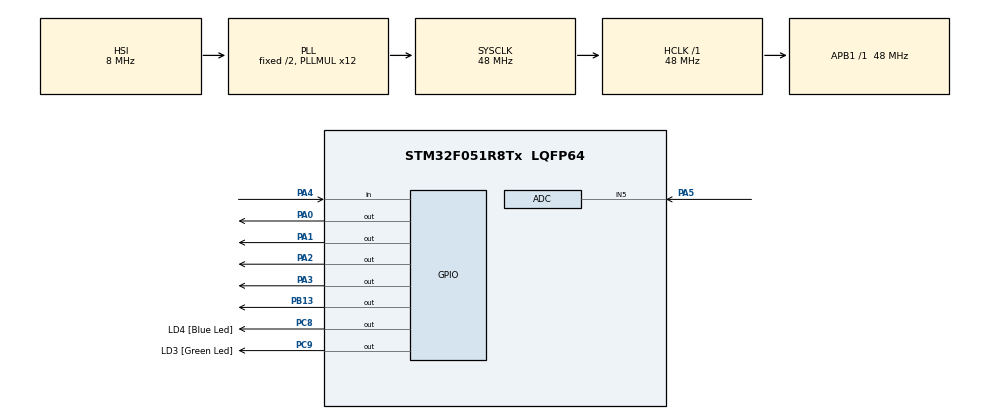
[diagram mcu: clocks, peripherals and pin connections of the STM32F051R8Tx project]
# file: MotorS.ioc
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ADC.ContinuousConvMode=ENABLE
Mcu.Family=STM32F0
Mcu.Name=STM32F051R8Tx
Mcu.Package=LQFP64
PA0.Signal=GPIO_Output
PA1.Signal=GPIO_Output
PA13.GPIO_Label=SWDIO
PA13.Mode=Serial_Wire
PA13.Signal=SYS_SWDIO
PA14.GPIO_Label=SWCLK
PA14.Mode=Serial_Wire
PA14.Signal=SYS_SWCLK
PA2.Signal=GPIO_Output
PA3.Signal=GPIO_Output
PA4.GPIO_PuPd=GPIO_PULLUP
PA4.Signal=GPIO_Input
PA5.Mode=IN5
PA5.Signal=ADC_IN5
PB13.Signal=GPIO_Output
PC8.GPIO_Label=LD4 [Blue Led]
PC8.Signal=GPIO_Output
PC9.GPIO_Label=LD3 [Green Led]
PC9.Signal=GPIO_Output
PF0-OSC_IN.Mode=HSE-External-Oscillator
PF0-OSC_IN.Signal=RCC_OSC_IN
PF1-OSC_OUT.Mode=HSE-External-Oscillator
PF1-OSC_OUT.Signal=RCC_OSC_OUT
ProjectManager.HeapSize=0x200
ProjectManager.StackSize=0x400
ProjectManager.TargetToolchain=STM32CubeIDE
RCC.AHBFreq_Value=48000000
RCC.APB1Freq_Value=48000000
RCC.APB1TimFreq_Value=48000000
RCC.HCLKFreq_Value=48000000
RCC.PLLMUL=RCC_PLL_MUL12
RCC.SYSCLKFreq_VALUE=48000000
RCC.SYSCLKSource=RCC_SYSCLKSOURCE_PLLCLK
TIM2.Prescaler=71
VP_TIM2_VS_ClockSourceINT.Mode=Internal
board=STM32F0DISCOVERY

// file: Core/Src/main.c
/* USER CODE BEGIN Header */
/**
  ******************************************************************************
  * @file           : main.c
  * @brief          : Main program body
  ******************************************************************************
  * @attention
  *
  * Copyright (c) 2024 STMicroelectronics.
  * All rights reserved.
  *
  * This software is licensed under terms that can be found in the LICENSE file
  * in the root directory of this software component.
  * If no LICENSE file comes with this software, it is provided AS-IS.
  *
  ******************************************************************************
  */
/* USER CODE END Header */
#include "main.h"

ADC_HandleTypeDef hadc;

TIM_HandleTypeDef htim2;

void SystemClock_Config(void);
static void MX_GPIO_Init(void);
static void MX_TIM2_Init(void);
static void MX_ADC_Init(void);

/* USER CODE BEGIN 0 */
int readValue;
#define IN1_PIN GPIO_PIN_0
#define IN1_PORT GPIOA
#define IN2_PIN GPIO_PIN_1
#define IN2_PORT GPIOA
#define IN3_PIN GPIO_PIN_2
#define IN3_PORT GPIOA
#define IN4_PIN GPIO_PIN_3
#define IN4_PORT GPIOA
int stepNumber;          // which step the motor is on

void motorDelay(uint32_t delay)
{
    if (delay < 6000)
    {
        __HAL_TIM_SET_COUNTER(&htim2, 0);
        while (__HAL_TIM_GET_COUNTER(&htim2) < delay);
    }
    else
    {
        HAL_Delay(delay/1000);
    }
}

void motorOn()
{
    // Find out which step the motor is on
    switch (stepNumber)
    {
      case 1:
          HAL_GPIO_WritePin(IN1_PORT, IN1_PIN, GPIO_PIN_SET);   // IN1
          HAL_GPIO_WritePin(IN2_PORT, IN2_PIN, GPIO_PIN_RESET); // IN2
          HAL_GPIO_WritePin(IN3_PORT, IN3_PIN, GPIO_PIN_RESET); // IN3
          HAL_GPIO_WritePin(IN4_PORT, IN4_PIN, GPIO_PIN_SET);   // IN4
          HAL_Delay(5);
        break;
      case 2:
          HAL_GPIO_WritePin(IN1_PORT, IN1_PIN, GPIO_PIN_SET);   // IN1
          HAL_GPIO_WritePin(IN2_PORT, IN2_PIN, GPIO_PIN_RESET); // IN2
          HAL_GPIO_WritePin(IN3_PORT, IN3_PIN, GPIO_PIN_SET);   // IN3
          HAL_GPIO_WritePin(IN4_PORT, IN4_PIN, GPIO_PIN_RESET); // IN4
          HAL_Delay(5);
        break;
      case 3:
          HAL_GPIO_WritePin(IN1_PORT, IN1_PIN, GPIO_PIN_RESET); // IN1
          HAL_GPIO_WritePin(IN2_PORT, IN2_PIN, GPIO_PIN_SET);   // IN2
          HAL_GPIO_WritePin(IN3_PORT, IN3_PIN, GPIO_PIN_SET);   // IN3
          HAL_GPIO_WritePin(IN4_PORT, IN4_PIN, GPIO_PIN_RESET); // IN4
          HAL_Delay(5);
        break;
      case 4:
          HAL_GPIO_WritePin(IN1_PORT, IN1_PIN, GPIO_PIN_RESET); // IN1
          HAL_GPIO_WritePin(IN2_PORT, IN2_PIN, GPIO_PIN_SET);   // IN2
          HAL_GPIO_WritePin(IN3_PORT, IN3_PIN, GPIO_PIN_RESET); // IN3
          HAL_GPIO_WritePin(IN4_PORT, IN4_PIN, GPIO_PIN_SET);   // IN4
          HAL_Delay(5);
        break;
      default:
        break;
    }
}
void motorOff()
{
    // Switch off the idle current to the motor
    // Otherwise L298N module will heat up
    HAL_GPIO_WritePin(IN1_PORT, IN1_PIN, GPIO_PIN_RESET); // IN1
    HAL_GPIO_WritePin(IN2_PORT, IN2_PIN, GPIO_PIN_RESET); // IN2
    HAL_GPIO_WritePin(IN3_PORT, IN3_PIN, GPIO_PIN_RESET); // IN3
    HAL_GPIO_WritePin(IN4_PORT, IN4_PIN, GPIO_PIN_RESET); // IN4
}
void stepCV (int steps, float speed) // CV - Clockwise
{
  uint32_t delay = 60*1000*1000/200/speed;
  for(int x=0; x<steps; x=x+1)
  {
    // Step to the next step
    switch (stepNumber)
    {
      case 1:
        HAL_GPIO_WritePin(IN1_PORT, IN1_PIN, GPIO_PIN_SET);   // IN1
        HAL_GPIO_WritePin(IN2_PORT, IN2_PIN, GPIO_PIN_RESET); // IN2
        HAL_GPIO_WritePin(IN3_PORT, IN3_PIN, GPIO_PIN_SET);   // IN3
        HAL_GPIO_WritePin(IN4_PORT, IN4_PIN, GPIO_PIN_RESET); // IN4
        motorDelay(delay);
        stepNumber = 2;
        break;
      case 2:
        HAL_GPIO_WritePin(IN1_PORT, IN1_PIN, GPIO_PIN_RESET); // IN1
        HAL_GPIO_WritePin(IN2_PORT, IN2_PIN, GPIO_PIN_SET);   // IN2
        HAL_GPIO_WritePin(IN3_PORT, IN3_PIN, GPIO_PIN_SET);   // IN3
        HAL_GPIO_WritePin(IN4_PORT, IN4_PIN, GPIO_PIN_RESET); // IN4
        motorDelay(delay);
        stepNumber = 3;
        break;
      case 3:

        HAL_GPIO_WritePin(IN1_PORT, IN1_PIN, GPIO_PIN_RESET); // IN1
        HAL_GPIO_WritePin(IN2_PORT, IN2_PIN, GPIO_PIN_SET);   // IN2
        HAL_GPIO_WritePin(IN3_PORT, IN3_PIN, GPIO_PIN_RESET); // IN3
        HAL_GPIO_WritePin(IN4_PORT, IN4_PIN, GPIO_PIN_SET);
        motorDelay(delay);
        stepNumber = 4;
        break;
      case 4:
        HAL_GPIO_WritePin(IN1_PORT, IN1_PIN, GPIO_PIN_SET);   // IN1
        HAL_GPIO_WritePin(IN2_PORT, IN2_PIN, GPIO_PIN_RESET); // IN2
        HAL_GPIO_WritePin(IN3_PORT, IN3_PIN, GPIO_PIN_RESET); // IN3
        HAL_GPIO_WritePin(IN4_PORT, IN4_PIN, GPIO_PIN_SET);   // IN4
        motorDelay(delay);
        stepNumber = 1;
        break;
      default:
        break;
    }
  }
}
void stepCCV (int steps, float speed) // CCV - Counter Clockwise
{
  uint32_t delay = 60*1000*1000/200/speed;
  for(int x=0; x<steps; x=x+1)
  {
    // Step to the previous step
    switch (stepNumber)
    {
      case 1:
        HAL_GPIO_WritePin(IN1_PORT, IN1_PIN, GPIO_PIN_RESET); // IN1
        HAL_GPIO_WritePin(IN2_PORT, IN2_PIN, GPIO_PIN_SET);   // IN2
        HAL_GPIO_WritePin(IN3_PORT, IN3_PIN, GPIO_PIN_RESET); // IN3
        HAL_GPIO_WritePin(IN4_PORT, IN4_PIN, GPIO_PIN_SET);   // IN4
        motorDelay(delay);
        stepNumber = 4;
        break;
      case 2:
        HAL_GPIO_WritePin(IN1_PORT, IN1_PIN, GPIO_PIN_SET);   // IN1
        HAL_GPIO_WritePin(IN2_PORT, IN2_PIN, GPIO_PIN_RESET); // IN2
        HAL_GPIO_WritePin(IN3_PORT, IN3_PIN, GPIO_PIN_RESET); // IN3
        HAL_GPIO_WritePin(IN4_PORT, IN4_PIN, GPIO_PIN_SET);   // IN4
        motorDelay(delay);
        stepNumber = 1;
        break;
      case 3:
        HAL_GPIO_WritePin(IN1_PORT, IN1_PIN, GPIO_PIN_SET);   // IN1
        HAL_GPIO_WritePin(IN2_PORT, IN2_PIN, GPIO_PIN_RESET); // IN2
        HAL_GPIO_WritePin(IN3_PORT, IN3_PIN, GPIO_PIN_SET);   // IN3
        HAL_GPIO_WritePin(IN4_PORT, IN4_PIN, GPIO_PIN_RESET); // IN4
        motorDelay(delay);
        stepNumber = 2;
        break;
      case 4:
        HAL_GPIO_WritePin(IN1_PORT, IN1_PIN, GPIO_PIN_RESET); // IN1
        HAL_GPIO_WritePin(IN2_PORT, IN2_PIN, GPIO_PIN_SET);   // IN2
        HAL_GPIO_WritePin(IN3_PORT, IN3_PIN, GPIO_PIN_SET);   // IN3
        HAL_GPIO_WritePin(IN4_PORT, IN4_PIN, GPIO_PIN_RESET); // IN4
        motorDelay(delay);
        stepNumber = 3;
        break;
      default:
        break;
    }
  }
}

/* USER CODE END 0 */

int main(void)
{

  /* MCU Configuration--------------------------------------------------------*/

  /* Reset of all peripherals, Initializes the Flash interface and the Systick. */
  HAL_Init();

  /* Configure the system clock */
  SystemClock_Config();

  /* Initialize all configured peripherals */
  MX_GPIO_Init();
  MX_TIM2_Init();
  MX_ADC_Init();
  /* USER CODE BEGIN 2 */
  HAL_TIM_Base_Start(&htim2);
  stepNumber = 1;
  HAL_ADC_Start(&hadc);

  /* USER CODE END 2 */

  /* Infinite loop */
  /* USER CODE BEGIN WHILE */
  while (1)
  {

	if(!HAL_GPIO_ReadPin(GPIOA, GPIO_PIN_4)){
	  	 motorOn();
	    stepCV(1000,150.0f); // Clockwise 200 steps 150 RPM
	    motorOff();
	    HAL_Delay(2000);

	    // motorOn();
	    	    // stepCCV(1000,150.0f); // Clockwise 200 steps 150 RPM
	    	    // motorOff();
	    	    // HAL_Delay(2000);
	}
	HAL_ADC_PollForConversion(&hadc, 1000);
	readValue=HAL_ADC_GetValue(&hadc);
	if(readValue<1000){
		HAL_GPIO_WritePin(GPIOB, GPIO_PIN_13, GPIO_PIN_RESET);
	}else if(readValue>1000){
		HAL_GPIO_WritePin(GPIOB, GPIO_PIN_13, GPIO_PIN_SET);
	}
    /* USER CODE END WHILE */

  }
}

void SystemClock_Config(void)
{
  RCC_OscInitTypeDef RCC_OscInitStruct = {0};
  RCC_ClkInitTypeDef RCC_ClkInitStruct = {0};

  /** Initializes the RCC Oscillators according to the specified parameters
  * in the RCC_OscInitTypeDef structure.
  */
  RCC_OscInitStruct.OscillatorType = RCC_OSCILLATORTYPE_HSI|RCC_OSCILLATORTYPE_HSI14;
  RCC_OscInitStruct.HSIState = RCC_HSI_ON;
  RCC_OscInitStruct.HSI14State = RCC_HSI14_ON;
  RCC_OscInitStruct.HSICalibrationValue = RCC_HSICALIBRATION_DEFAULT;
  RCC_OscInitStruct.HSI14CalibrationValue = 16;
  RCC_OscInitStruct.PLL.PLLState = RCC_PLL_ON;
  RCC_OscInitStruct.PLL.PLLSource = RCC_PLLSOURCE_HSI;
  RCC_OscInitStruct.PLL.PLLMUL = RCC_PLL_MUL12;
  RCC_OscInitStruct.PLL.PREDIV = RCC_PREDIV_DIV1;
  if (HAL_RCC_OscConfig(&RCC_OscInitStruct) != HAL_OK)
  {
    Error_Handler();
  }

  /** Initializes the CPU, AHB and APB buses clocks
  */
  RCC_ClkInitStruct.ClockType = RCC_CLOCKTYPE_HCLK|RCC_CLOCKTYPE_SYSCLK
                              |RCC_CLOCKTYPE_PCLK1;
  RCC_ClkInitStruct.SYSCLKSource = RCC_SYSCLKSOURCE_PLLCLK;
  RCC_ClkInitStruct.AHBCLKDivider = RCC_SYSCLK_DIV1;
  RCC_ClkInitStruct.APB1CLKDivider = RCC_HCLK_DIV1;

  if (HAL_RCC_ClockConfig(&RCC_ClkInitStruct, FLASH_LATENCY_1) != HAL_OK)
  {
    Error_Handler();
  }
}

static void MX_ADC_Init(void)
{

  ADC_ChannelConfTypeDef sConfig = {0};

  /** Configure the global features of the ADC (Clock, Resolution, Data Alignment and number of conversion)
  */
  hadc.Instance = ADC1;
  hadc.Init.ClockPrescaler = ADC_CLOCK_ASYNC_DIV1;
  hadc.Init.Resolution = ADC_RESOLUTION_12B;
  hadc.Init.DataAlign = ADC_DATAALIGN_RIGHT;
  hadc.Init.ScanConvMode = ADC_SCAN_DIRECTION_FORWARD;
  hadc.Init.EOCSelection = ADC_EOC_SINGLE_CONV;
  hadc.Init.LowPowerAutoWait = DISABLE;
  hadc.Init.LowPowerAutoPowerOff = DISABLE;
  hadc.Init.ContinuousConvMode = ENABLE;
  hadc.Init.DiscontinuousConvMode = DISABLE;
  hadc.Init.ExternalTrigConv = ADC_SOFTWARE_START;
  hadc.Init.ExternalTrigConvEdge = ADC_EXTERNALTRIGCONVEDGE_NONE;
  hadc.Init.DMAContinuousRequests = DISABLE;
  hadc.Init.Overrun = ADC_OVR_DATA_PRESERVED;
  if (HAL_ADC_Init(&hadc) != HAL_OK)
  {
    Error_Handler();
  }

  /** Configure for the selected ADC regular channel to be converted.
  */
  sConfig.Channel = ADC_CHANNEL_5;
  sConfig.Rank = ADC_RANK_CHANNEL_NUMBER;
  sConfig.SamplingTime = ADC_SAMPLETIME_1CYCLE_5;
  if (HAL_ADC_ConfigChannel(&hadc, &sConfig) != HAL_OK)
  {
    Error_Handler();
  }

}

static void MX_TIM2_Init(void)
{

  TIM_ClockConfigTypeDef sClockSourceConfig = {0};
  TIM_MasterConfigTypeDef sMasterConfig = {0};

  htim2.Instance = TIM2;
  htim2.Init.Prescaler = 71;
  htim2.Init.CounterMode = TIM_COUNTERMODE_UP;
  htim2.Init.Period = 4294967295;
  htim2.Init.ClockDivision = TIM_CLOCKDIVISION_DIV1;
  htim2.Init.AutoReloadPreload = TIM_AUTORELOAD_PRELOAD_DISABLE;
  if (HAL_TIM_Base_Init(&htim2) != HAL_OK)
  {
    Error_Handler();
  }
  sClockSourceConfig.ClockSource = TIM_CLOCKSOURCE_INTERNAL;
  if (HAL_TIM_ConfigClockSource(&htim2, &sClockSourceConfig) != HAL_OK)
  {
    Error_Handler();
  }
  sMasterConfig.MasterOutputTrigger = TIM_TRGO_RESET;
  sMasterConfig.MasterSlaveMode = TIM_MASTERSLAVEMODE_DISABLE;
  if (HAL_TIMEx_MasterConfigSynchronization(&htim2, &sMasterConfig) != HAL_OK)
  {
    Error_Handler();
  }

}

static void MX_GPIO_Init(void)
{
  GPIO_InitTypeDef GPIO_InitStruct = {0};

  /* GPIO Ports Clock Enable */
  __HAL_RCC_GPIOF_CLK_ENABLE();
  __HAL_RCC_GPIOA_CLK_ENABLE();
  __HAL_RCC_GPIOB_CLK_ENABLE();
  __HAL_RCC_GPIOC_CLK_ENABLE();

  /*Configure GPIO pin Output Level */
  HAL_GPIO_WritePin(GPIOA, GPIO_PIN_0|GPIO_PIN_1|GPIO_PIN_2|GPIO_PIN_3, GPIO_PIN_RESET);

  /*Configure GPIO pin Output Level */
  HAL_GPIO_WritePin(GPIOB, GPIO_PIN_13, GPIO_PIN_RESET);

  /*Configure GPIO pin Output Level */
  HAL_GPIO_WritePin(GPIOC, LD4_Pin|LD3_Pin, GPIO_PIN_RESET);

  /*Configure GPIO pins : PA0 PA1 PA2 PA3 */
  GPIO_InitStruct.Pin = GPIO_PIN_0|GPIO_PIN_1|GPIO_PIN_2|GPIO_PIN_3;
  GPIO_InitStruct.Mode = GPIO_MODE_OUTPUT_PP;
  GPIO_InitStruct.Pull = GPIO_NOPULL;
  GPIO_InitStruct.Speed = GPIO_SPEED_FREQ_LOW;
  HAL_GPIO_Init(GPIOA, &GPIO_InitStruct);

  /*Configure GPIO pin : PA4 */
  GPIO_InitStruct.Pin = GPIO_PIN_4;
  GPIO_InitStruct.Mode = GPIO_MODE_INPUT;
  GPIO_InitStruct.Pull = GPIO_PULLUP;
  HAL_GPIO_Init(GPIOA, &GPIO_InitStruct);

  /*Configure GPIO pin : PB13 */
  GPIO_InitStruct.Pin = GPIO_PIN_13;
  GPIO_InitStruct.Mode = GPIO_MODE_OUTPUT_PP;
  GPIO_InitStruct.Pull = GPIO_NOPULL;
  GPIO_InitStruct.Speed = GPIO_SPEED_FREQ_LOW;
  HAL_GPIO_Init(GPIOB, &GPIO_InitStruct);

  /*Configure GPIO pins : LD4_Pin LD3_Pin */
  GPIO_InitStruct.Pin = LD4_Pin|LD3_Pin;
  GPIO_InitStruct.Mode = GPIO_MODE_OUTPUT_PP;
  GPIO_InitStruct.Pull = GPIO_NOPULL;
  GPIO_InitStruct.Speed = GPIO_SPEED_FREQ_LOW;
  HAL_GPIO_Init(GPIOC, &GPIO_InitStruct);

}

void Error_Handler(void)
{
  __disable_irq();
  while (1)
  {
  }
}
